# SYSCTRL_PADCONF_CORE register map
Vendor: Texas Instruments
Registers are 32-bit, access per field, reset 0x10F010F unless marked. A register's access mark holds for its fields unless they carry their own. Offsets are as the file gives them; [hi:lo] are bit positions; 'fields as' and 'values as' point back to an identical list.

## SYSCTRL_PADCONF_CORE (part 3 of 10)
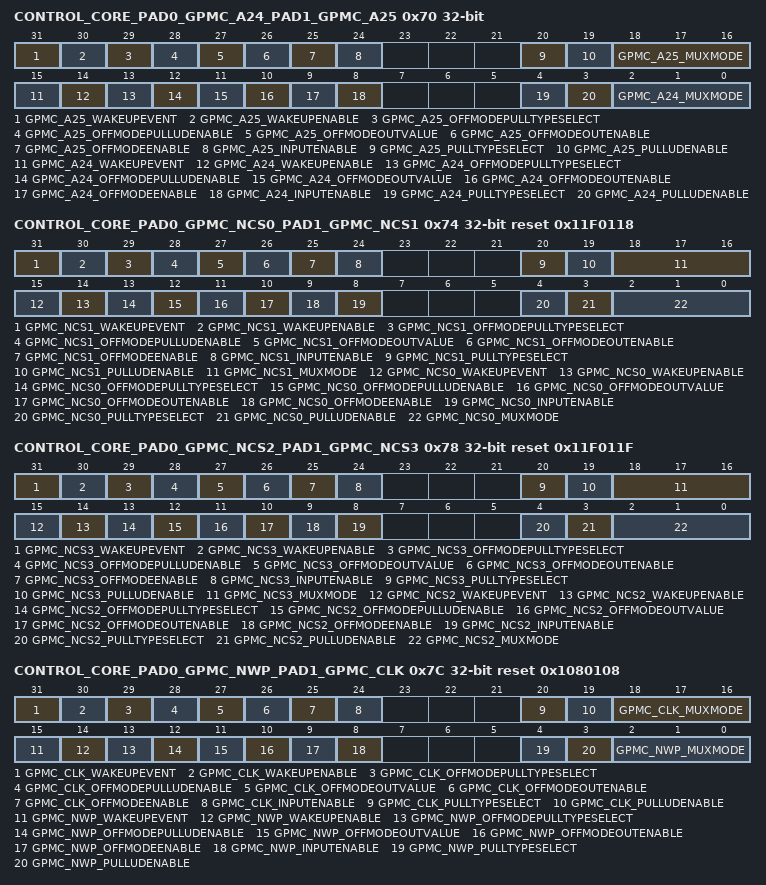
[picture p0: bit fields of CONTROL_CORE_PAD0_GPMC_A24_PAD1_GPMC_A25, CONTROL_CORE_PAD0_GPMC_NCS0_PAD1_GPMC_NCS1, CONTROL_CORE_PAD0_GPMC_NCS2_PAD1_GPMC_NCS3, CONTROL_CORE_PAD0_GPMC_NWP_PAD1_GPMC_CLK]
0x70 CONTROL_CORE_PAD0_GPMC_A24_PAD1_GPMC_A25 — Register control for Pads gpmc_a24 and gpmc_a25 Access conditions. Read: unrestricted, Write: unrestricted
  [31] GPMC_A25_WAKEUPEVENT ro — Pad_x wake-up event status latched in the IO
    0=GPMC_A25_WAKEUPEVENT_0_r (No wake-up event occurred); 1=GPMC_A25_WAKEUPEVENT_1_r (A wake-up event occurred)
  [30] GPMC_A25_WAKEUPENABLE rw — Input pad wake-up enable (and OFF mode input enable value)
    0=wake-up detection is disabled; 1=wake-up detection is enabled
  [29] GPMC_A25_OFFMODEPULLTYPESELECT rw — OffMode mode pullup/down selection for pad gpmc_a25
    0=Offmode pulldown selected; 1=Offmode pullup selected
  [28] GPMC_A25_OFFMODEPULLUDENABLE rw — OffMode mode pullup/down enable for pad gpmc_a25
    0=Offmode pullup/down disabled; 1=Offmode pullup/down enabled
  [27] GPMC_A25_OFFMODEOUTVALUE rw — OffMode mode output value for pad gpmc_a25
    0=Set value at 0; 1=Set value at 1
  [26] GPMC_A25_OFFMODEOUTENABLE rw — OffMode mode output enable value for pad gpmc_a25. This is an active low signal
    0=Output enable; 1=Output disable
  [25] GPMC_A25_OFFMODEENABLE rw — OffMode mode override control for pad gpmc_a25
    0=I/O state keeps its previous state when OFF mode is active; 1=I/O state is forced to OFF mode value when OFF mode is active
  [24] GPMC_A25_INPUTENABLE rw — Input enable value for pad gpmc_a25
    0=Input buffer of I/O cell is disabled; 1=Input buffer of I/O cell is enabled
  [20] GPMC_A25_PULLTYPESELECT rw — pullup/down selection for pad gpmc_a25
    0=pulldown selected; 1=pullup selected
  [19] GPMC_A25_PULLUDENABLE rw — pullup/down enable for pad gpmc_a25
    0=pullup/down disabled; 1=pullup/down enabled
  [18:16] GPMC_A25_MUXMODE rw — Functional multiplexing selection for pad gpmc_a25
    0=Select gpmc_a25; 2=Select c2c_clkout1; 3=Select gpio_49; 7=Select safe_mode
  [15] GPMC_A24_WAKEUPEVENT ro — Pad_x wake-up event status latched in the IO
    0=GPMC_A24_WAKEUPEVENT_0_r (No wake-up event occurred); 1=GPMC_A24_WAKEUPEVENT_1_r (A wake-up event occurred)
  [14] GPMC_A24_WAKEUPENABLE rw — Input pad wake-up enable (and OFF mode input enable value)
    values as GPMC_A25_WAKEUPENABLE
  [13] GPMC_A24_OFFMODEPULLTYPESELECT rw — OffMode mode pullup/down selection for pad gpmc_a24
    0=Offmode pulldown selected; 1=Offmode pullup selected
  [12] GPMC_A24_OFFMODEPULLUDENABLE rw — OffMode mode pullup/down enable for pad gpmc_a24
    values as GPMC_A25_OFFMODEPULLUDENABLE
  [11] GPMC_A24_OFFMODEOUTVALUE rw — OffMode mode output value for pad gpmc_a24
    0=Set value at 0; 1=Set value at 1
  [10] GPMC_A24_OFFMODEOUTENABLE rw — OffMode mode output enable value for pad gpmc_a24. This is an active low signal
    0=Output enable; 1=Output disable
  [9] GPMC_A24_OFFMODEENABLE rw — OffMode mode override control for pad gpmc_a24
    values as GPMC_A25_OFFMODEENABLE
  [8] GPMC_A24_INPUTENABLE rw — Input enable value for pad gpmc_a24
    values as GPMC_A25_INPUTENABLE
  [4] GPMC_A24_PULLTYPESELECT rw — pullup/down selection for pad gpmc_a24
    0=pulldown selected; 1=pullup selected
  [3] GPMC_A24_PULLUDENABLE rw — pullup/down enable for pad gpmc_a24
    0=pullup/down disabled; 1=pullup/down enabled
  [2:0] GPMC_A24_MUXMODE rw — Functional multiplexing selection for pad gpmc_a24
    0=Select gpmc_a24; 1=Select kpd_col8; 2=Select c2c_clkout0; 3=Select gpio_48; 7=Select safe_mode
0x74 CONTROL_CORE_PAD0_GPMC_NCS0_PAD1_GPMC_NCS1 reset 0x11F0118 — Register control for Pads gpmc_ncs0 and gpmc_ncs1 Access conditions. Read: unrestricted, Write: unrestricted
  [31] GPMC_NCS1_WAKEUPEVENT ro — Pad_x wake-up event status latched in the IO
    0=GPMC_NCS1_WAKEUPEVENT_0_r (No wake-up event occurred); 1=GPMC_NCS1_WAKEUPEVENT_1_r (A wake-up event occurred)
  [30] GPMC_NCS1_WAKEUPENABLE rw — Input pad wake-up enable (and OFF mode input enable value)
    values as CONTROL_CORE_PAD0_GPMC_A24_PAD1_GPMC_A25.GPMC_A25_WAKEUPENABLE
  [29] GPMC_NCS1_OFFMODEPULLTYPESELECT rw — OffMode mode pullup/down selection for pad gpmc_ncs1
    0=Offmode pulldown selected; 1=Offmode pullup selected
  [28] GPMC_NCS1_OFFMODEPULLUDENABLE rw — OffMode mode pullup/down enable for pad gpmc_ncs1
    values as CONTROL_CORE_PAD0_GPMC_A24_PAD1_GPMC_A25.GPMC_A25_OFFMODEPULLUDENABLE
  [27] GPMC_NCS1_OFFMODEOUTVALUE rw — OffMode mode output value for pad gpmc_ncs1
    0=Set value at 0; 1=Set value at 1
  [26] GPMC_NCS1_OFFMODEOUTENABLE rw — OffMode mode output enable value for pad gpmc_ncs1. This is an active low signal
    0=Output enable; 1=Output disable
  [25] GPMC_NCS1_OFFMODEENABLE rw — OffMode mode override control for pad gpmc_ncs1
    values as CONTROL_CORE_PAD0_GPMC_A24_PAD1_GPMC_A25.GPMC_A25_OFFMODEENABLE
  [24] GPMC_NCS1_INPUTENABLE rw — Input enable value for pad gpmc_ncs1
    values as CONTROL_CORE_PAD0_GPMC_A24_PAD1_GPMC_A25.GPMC_A25_INPUTENABLE
  [20] GPMC_NCS1_PULLTYPESELECT rw — pullup/down selection for pad gpmc_ncs1
    0=pulldown selected; 1=pullup selected
  [19] GPMC_NCS1_PULLUDENABLE rw — pullup/down enable for pad gpmc_ncs1
    0=pullup/down disabled; 1=pullup/down enabled
  [18:16] GPMC_NCS1_MUXMODE rw — Functional multiplexing selection for pad gpmc_ncs1
    0=Select gpmc_ncs1; 2=Select c2c_dataout6; 3=Select gpio_51; 7=Select safe_mode
  [15] GPMC_NCS0_WAKEUPEVENT ro — Pad_x wake-up event status latched in the IO
    0=GPMC_NCS0_WAKEUPEVENT_0_r (No wake-up event occurred); 1=GPMC_NCS0_WAKEUPEVENT_1_r (A wake-up event occurred)
  [14] GPMC_NCS0_WAKEUPENABLE rw — Input pad wake-up enable (and OFF mode input enable value)
    values as CONTROL_CORE_PAD0_GPMC_A24_PAD1_GPMC_A25.GPMC_A25_WAKEUPENABLE
  [13] GPMC_NCS0_OFFMODEPULLTYPESELECT rw — OffMode mode pullup/down selection for pad gpmc_ncs0
    0=Offmode pulldown selected; 1=Offmode pullup selected
  [12] GPMC_NCS0_OFFMODEPULLUDENABLE rw — OffMode mode pullup/down enable for pad gpmc_ncs0
    values as CONTROL_CORE_PAD0_GPMC_A24_PAD1_GPMC_A25.GPMC_A25_OFFMODEPULLUDENABLE
  [11] GPMC_NCS0_OFFMODEOUTVALUE rw — OffMode mode output value for pad gpmc_ncs0
    0=Set value at 0; 1=Set value at 1
  [10] GPMC_NCS0_OFFMODEOUTENABLE rw — OffMode mode output enable value for pad gpmc_ncs0. This is an active low signal
    0=Output enable; 1=Output disable
  [9] GPMC_NCS0_OFFMODEENABLE rw — OffMode mode override control for pad gpmc_ncs0
    values as CONTROL_CORE_PAD0_GPMC_A24_PAD1_GPMC_A25.GPMC_A25_OFFMODEENABLE
  [8] GPMC_NCS0_INPUTENABLE rw — Input enable value for pad gpmc_ncs0
    values as CONTROL_CORE_PAD0_GPMC_A24_PAD1_GPMC_A25.GPMC_A25_INPUTENABLE
  [4] GPMC_NCS0_PULLTYPESELECT rw — pullup/down selection for pad gpmc_ncs0
    0=pulldown selected; 1=pullup selected
  [3] GPMC_NCS0_PULLUDENABLE rw — pullup/down enable for pad gpmc_ncs0
    0=pullup/down disabled; 1=pullup/down enabled
  [2:0] GPMC_NCS0_MUXMODE rw — Functional multiplexing selection for pad gpmc_ncs0
    0=Select gpmc_ncs0; 3=Select gpio_50; 4=Select sys_ndmareq0
0x78 CONTROL_CORE_PAD0_GPMC_NCS2_PAD1_GPMC_NCS3 reset 0x11F011F — Register control for Pads gpmc_ncs2 and gpmc_ncs3 Access conditions. Read: unrestricted, Write: unrestricted
  [31] GPMC_NCS3_WAKEUPEVENT ro — Pad_x wake-up event status latched in the IO
    0=GPMC_NCS3_WAKEUPEVENT_0_r (No wake-up event occurred); 1=GPMC_NCS3_WAKEUPEVENT_1_r (A wake-up event occurred)
  [30] GPMC_NCS3_WAKEUPENABLE rw — Input pad wake-up enable (and OFF mode input enable value)
    values as CONTROL_CORE_PAD0_GPMC_A24_PAD1_GPMC_A25.GPMC_A25_WAKEUPENABLE
  [29] GPMC_NCS3_OFFMODEPULLTYPESELECT rw — OffMode mode pullup/down selection for pad gpmc_ncs3
    0=Offmode pulldown selected; 1=Offmode pullup selected
  [28] GPMC_NCS3_OFFMODEPULLUDENABLE rw — OffMode mode pullup/down enable for pad gpmc_ncs3
    values as CONTROL_CORE_PAD0_GPMC_A24_PAD1_GPMC_A25.GPMC_A25_OFFMODEPULLUDENABLE
  [27] GPMC_NCS3_OFFMODEOUTVALUE rw — OffMode mode output value for pad gpmc_ncs3
    0=Set value at 0; 1=Set value at 1
  [26] GPMC_NCS3_OFFMODEOUTENABLE rw — OffMode mode output enable value for pad gpmc_ncs3. This is an active low signal
    0=Output enable; 1=Output disable
  [25] GPMC_NCS3_OFFMODEENABLE rw — OffMode mode override control for pad gpmc_ncs3
    values as CONTROL_CORE_PAD0_GPMC_A24_PAD1_GPMC_A25.GPMC_A25_OFFMODEENABLE
  [24] GPMC_NCS3_INPUTENABLE rw — Input enable value for pad gpmc_ncs3
    values as CONTROL_CORE_PAD0_GPMC_A24_PAD1_GPMC_A25.GPMC_A25_INPUTENABLE
  [20] GPMC_NCS3_PULLTYPESELECT rw — pullup/down selection for pad gpmc_ncs3
    0=pulldown selected; 1=pullup selected
  [19] GPMC_NCS3_PULLUDENABLE rw — pullup/down enable for pad gpmc_ncs3
    0=pullup/down disabled; 1=pullup/down enabled
  [18:16] GPMC_NCS3_MUXMODE rw — Functional multiplexing selection for pad gpmc_ncs3
    0=Select gpmc_ncs3; 1=Select gpmc_dir; 2=Select c2c_dataout4; 3=Select gpio_53; 7=Select safe_mode
  [15] GPMC_NCS2_WAKEUPEVENT ro — Pad_x wake-up event status latched in the IO
    0=GPMC_NCS2_WAKEUPEVENT_0_r (No wake-up event occurred); 1=GPMC_NCS2_WAKEUPEVENT_1_r (A wake-up event occurred)
  [14] GPMC_NCS2_WAKEUPENABLE rw — Input pad wake-up enable (and OFF mode input enable value)
    values as CONTROL_CORE_PAD0_GPMC_A24_PAD1_GPMC_A25.GPMC_A25_WAKEUPENABLE
  [13] GPMC_NCS2_OFFMODEPULLTYPESELECT rw — OffMode mode pullup/down selection for pad gpmc_ncs2
    0=Offmode pulldown selected; 1=Offmode pullup selected
  [12] GPMC_NCS2_OFFMODEPULLUDENABLE rw — OffMode mode pullup/down enable for pad gpmc_ncs2
    values as CONTROL_CORE_PAD0_GPMC_A24_PAD1_GPMC_A25.GPMC_A25_OFFMODEPULLUDENABLE
  [11] GPMC_NCS2_OFFMODEOUTVALUE rw — OffMode mode output value for pad gpmc_ncs2
    0=Set value at 0; 1=Set value at 1
  [10] GPMC_NCS2_OFFMODEOUTENABLE rw — OffMode mode output enable value for pad gpmc_ncs2. This is an active low signal
    0=Output enable; 1=Output disable
  [9] GPMC_NCS2_OFFMODEENABLE rw — OffMode mode override control for pad gpmc_ncs2
    values as CONTROL_CORE_PAD0_GPMC_A24_PAD1_GPMC_A25.GPMC_A25_OFFMODEENABLE
  [8] GPMC_NCS2_INPUTENABLE rw — Input enable value for pad gpmc_ncs2
    values as CONTROL_CORE_PAD0_GPMC_A24_PAD1_GPMC_A25.GPMC_A25_INPUTENABLE
  [4] GPMC_NCS2_PULLTYPESELECT rw — pullup/down selection for pad gpmc_ncs2
    0=pulldown selected; 1=pullup selected
  [3] GPMC_NCS2_PULLUDENABLE rw — pullup/down enable for pad gpmc_ncs2
    0=pullup/down disabled; 1=pullup/down enabled
  [2:0] GPMC_NCS2_MUXMODE rw — Functional multiplexing selection for pad gpmc_ncs2
    0=Select gpmc_ncs2; 1=Select kpd_row8; 2=Select c2c_dataout7; 3=Select gpio_52; 7=Select safe_mode
0x7C CONTROL_CORE_PAD0_GPMC_NWP_PAD1_GPMC_CLK reset 0x1080108 — Register control for Pads gpmc_nwp and gpmc_clk Access conditions. Read: unrestricted, Write: unrestricted
  [31] GPMC_CLK_WAKEUPEVENT ro — Pad_x wake-up event status latched in the IO
    0=GPMC_CLK_WAKEUPEVENT_0_r (No wake-up event occurred); 1=GPMC_CLK_WAKEUPEVENT_1_r (A wake-up event occurred)
  [30] GPMC_CLK_WAKEUPENABLE rw — Input pad wake-up enable (and OFF mode input enable value)
    values as CONTROL_CORE_PAD0_GPMC_A24_PAD1_GPMC_A25.GPMC_A25_WAKEUPENABLE
  [29] GPMC_CLK_OFFMODEPULLTYPESELECT rw — OffMode mode pullup/down selection for pad gpmc_clk
    0=Offmode pulldown selected; 1=Offmode pullup selected
  [28] GPMC_CLK_OFFMODEPULLUDENABLE rw — OffMode mode pullup/down enable for pad gpmc_clk
    values as CONTROL_CORE_PAD0_GPMC_A24_PAD1_GPMC_A25.GPMC_A25_OFFMODEPULLUDENABLE
  [27] GPMC_CLK_OFFMODEOUTVALUE rw — OffMode mode output value for pad gpmc_clk
    0=Set value at 0; 1=Set value at 1
  [26] GPMC_CLK_OFFMODEOUTENABLE rw — OffMode mode output enable value for pad gpmc_clk. This is an active low signal
    0=Output enable; 1=Output disable
  [25] GPMC_CLK_OFFMODEENABLE rw — OffMode mode override control for pad gpmc_clk
    values as CONTROL_CORE_PAD0_GPMC_A24_PAD1_GPMC_A25.GPMC_A25_OFFMODEENABLE
  [24] GPMC_CLK_INPUTENABLE rw — Input enable value for pad gpmc_clk
    values as CONTROL_CORE_PAD0_GPMC_A24_PAD1_GPMC_A25.GPMC_A25_INPUTENABLE
  [20] GPMC_CLK_PULLTYPESELECT rw — pullup/down selection for pad gpmc_clk
    0=pulldown selected; 1=pullup selected
  [19] GPMC_CLK_PULLUDENABLE rw — pullup/down enable for pad gpmc_clk
    0=pullup/down disabled; 1=pullup/down enabled
  [18:16] GPMC_CLK_MUXMODE rw — Functional multiplexing selection for pad gpmc_clk
    0=Select gpmc_clk; 3=Select gpio_55; 4=Select sys_ndmareq2; 5=Select sdmmc1_cmd
  [15] GPMC_NWP_WAKEUPEVENT ro — Pad_x wake-up event status latched in the IO
    0=GPMC_NWP_WAKEUPEVENT_0_r (No wake-up event occurred); 1=GPMC_NWP_WAKEUPEVENT_1_r (A wake-up event occurred)
  [14] GPMC_NWP_WAKEUPENABLE rw — Input pad wake-up enable (and OFF mode input enable value)
    values as CONTROL_CORE_PAD0_GPMC_A24_PAD1_GPMC_A25.GPMC_A25_WAKEUPENABLE
  [13] GPMC_NWP_OFFMODEPULLTYPESELECT rw — OffMode mode pullup/down selection for pad gpmc_nwp
    0=Offmode pulldown selected; 1=Offmode pullup selected
  [12] GPMC_NWP_OFFMODEPULLUDENABLE rw — OffMode mode pullup/down enable for pad gpmc_nwp
    values as CONTROL_CORE_PAD0_GPMC_A24_PAD1_GPMC_A25.GPMC_A25_OFFMODEPULLUDENABLE
  [11] GPMC_NWP_OFFMODEOUTVALUE rw — OffMode mode output value for pad gpmc_nwp
    0=Set value at 0; 1=Set value at 1
  [10] GPMC_NWP_OFFMODEOUTENABLE rw — OffMode mode output enable value for pad gpmc_nwp. This is an active low signal
    0=Output enable; 1=Output disable
  [9] GPMC_NWP_OFFMODEENABLE rw — OffMode mode override control for pad gpmc_nwp
    values as CONTROL_CORE_PAD0_GPMC_A24_PAD1_GPMC_A25.GPMC_A25_OFFMODEENABLE
  [8] GPMC_NWP_INPUTENABLE rw — Input enable value for pad gpmc_nwp
    values as CONTROL_CORE_PAD0_GPMC_A24_PAD1_GPMC_A25.GPMC_A25_INPUTENABLE
  [4] GPMC_NWP_PULLTYPESELECT rw — pullup/down selection for pad gpmc_nwp
    0=pulldown selected; 1=pullup selected
  [3] GPMC_NWP_PULLUDENABLE rw — pullup/down enable for pad gpmc_nwp
    0=pullup/down disabled; 1=pullup/down enabled
  [2:0] GPMC_NWP_MUXMODE rw — Functional multiplexing selection for pad gpmc_nwp
    0=Select gpmc_nwp; 1=Select dsi1_te0; 3=Select gpio_54; 4=Select sys_ndmareq1
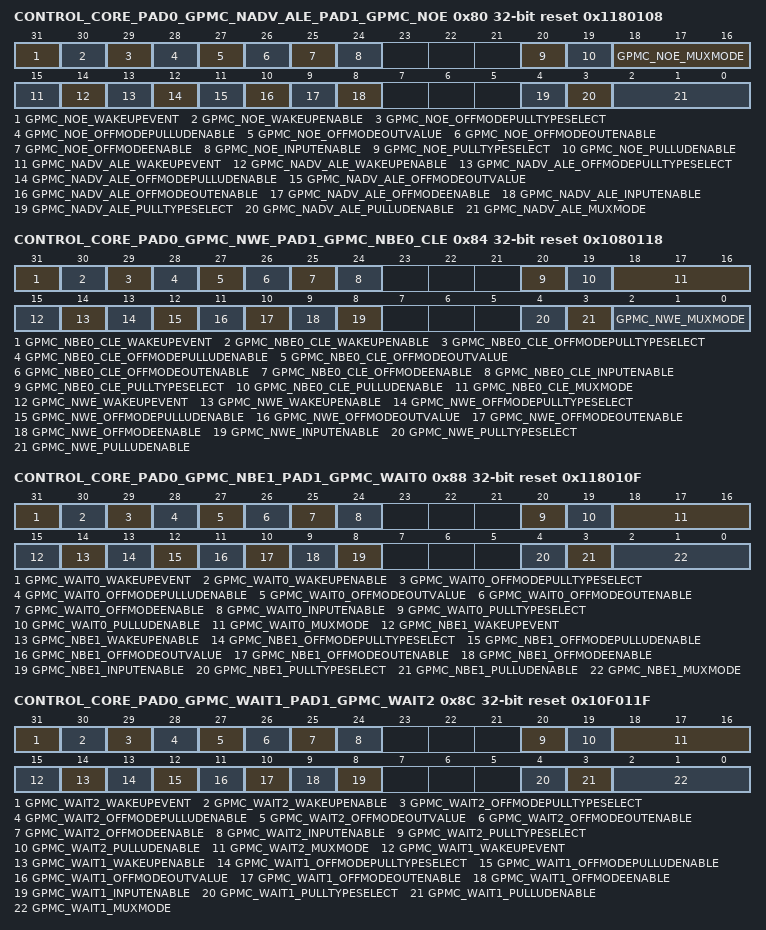
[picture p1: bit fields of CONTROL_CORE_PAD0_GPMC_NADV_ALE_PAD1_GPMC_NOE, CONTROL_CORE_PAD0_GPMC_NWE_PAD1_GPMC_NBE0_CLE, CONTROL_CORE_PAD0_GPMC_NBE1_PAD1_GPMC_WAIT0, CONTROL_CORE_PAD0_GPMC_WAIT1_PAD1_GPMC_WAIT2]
0x80 CONTROL_CORE_PAD0_GPMC_NADV_ALE_PAD1_GPMC_NOE reset 0x1180108 — Register control for Pads gpmc_nadv_ale and gpmc_noe Access conditions. Read: unrestricted, Write: unrestricted
  [31] GPMC_NOE_WAKEUPEVENT ro — Pad_x wake-up event status latched in the IO
    0=GPMC_NOE_WAKEUPEVENT_0_r (No wake-up event occurred); 1=GPMC_NOE_WAKEUPEVENT_1_r (A wake-up event occurred)
  [30] GPMC_NOE_WAKEUPENABLE rw — Input pad wake-up enable (and OFF mode input enable value)
    values as CONTROL_CORE_PAD0_GPMC_A24_PAD1_GPMC_A25.GPMC_A25_WAKEUPENABLE
  [29] GPMC_NOE_OFFMODEPULLTYPESELECT rw — OffMode mode pullup/down selection for pad gpmc_noe
    0=Offmode pulldown selected; 1=Offmode pullup selected
  [28] GPMC_NOE_OFFMODEPULLUDENABLE rw — OffMode mode pullup/down enable for pad gpmc_noe
    values as CONTROL_CORE_PAD0_GPMC_A24_PAD1_GPMC_A25.GPMC_A25_OFFMODEPULLUDENABLE
  [27] GPMC_NOE_OFFMODEOUTVALUE rw — OffMode mode output value for pad gpmc_noe
    0=Set value at 0; 1=Set value at 1
  [26] GPMC_NOE_OFFMODEOUTENABLE rw — OffMode mode output enable value for pad gpmc_noe. This is an active low signal
    0=Output enable; 1=Output disable
  [25] GPMC_NOE_OFFMODEENABLE rw — OffMode mode override control for pad gpmc_noe
    values as CONTROL_CORE_PAD0_GPMC_A24_PAD1_GPMC_A25.GPMC_A25_OFFMODEENABLE
  [24] GPMC_NOE_INPUTENABLE rw — Input enable value for pad gpmc_noe
    values as CONTROL_CORE_PAD0_GPMC_A24_PAD1_GPMC_A25.GPMC_A25_INPUTENABLE
  [20] GPMC_NOE_PULLTYPESELECT rw — pullup/down selection for pad gpmc_noe
    0=pulldown selected; 1=pullup selected
  [19] GPMC_NOE_PULLUDENABLE rw — pullup/down enable for pad gpmc_noe
    0=pullup/down disabled; 1=pullup/down enabled
  [18:16] GPMC_NOE_MUXMODE rw — Functional multiplexing selection for pad gpmc_noe
    0=Select gpmc_noe; 1=Select sdmmc2_clk
  [15] GPMC_NADV_ALE_WAKEUPEVENT ro — Pad_x wake-up event status latched in the IO
    0=GPMC_NADV_ALE_WAKEUPEVENT_0_r (No wake-up event occurred); 1=GPMC_NADV_ALE_WAKEUPEVENT_1_r (A wake-up event occurred)
  [14] GPMC_NADV_ALE_WAKEUPENABLE rw — Input pad wake-up enable (and OFF mode input enable value)
    values as CONTROL_CORE_PAD0_GPMC_A24_PAD1_GPMC_A25.GPMC_A25_WAKEUPENABLE
  [13] GPMC_NADV_ALE_OFFMODEPULLTYPESELECT rw — OffMode mode pullup/down selection for pad gpmc_nadv_ale
    0=Offmode pulldown selected; 1=Offmode pullup selected
  [12] GPMC_NADV_ALE_OFFMODEPULLUDENABLE rw — OffMode mode pullup/down enable for pad gpmc_nadv_ale
    values as CONTROL_CORE_PAD0_GPMC_A24_PAD1_GPMC_A25.GPMC_A25_OFFMODEPULLUDENABLE
  [11] GPMC_NADV_ALE_OFFMODEOUTVALUE rw — OffMode mode output value for pad gpmc_nadv_ale
    0=Set value at 0; 1=Set value at 1
  [10] GPMC_NADV_ALE_OFFMODEOUTENABLE rw — OffMode mode output enable value for pad gpmc_nadv_ale. This is an active low signal
    0=Output enable; 1=Output disable
  [9] GPMC_NADV_ALE_OFFMODEENABLE rw — OffMode mode override control for pad gpmc_nadv_ale
    values as CONTROL_CORE_PAD0_GPMC_A24_PAD1_GPMC_A25.GPMC_A25_OFFMODEENABLE
  [8] GPMC_NADV_ALE_INPUTENABLE rw — Input enable value for pad gpmc_nadv_ale
    values as CONTROL_CORE_PAD0_GPMC_A24_PAD1_GPMC_A25.GPMC_A25_INPUTENABLE
  [4] GPMC_NADV_ALE_PULLTYPESELECT rw — pullup/down selection for pad gpmc_nadv_ale
    0=pulldown selected; 1=pullup selected
  [3] GPMC_NADV_ALE_PULLUDENABLE rw — pullup/down enable for pad gpmc_nadv_ale
    0=pullup/down disabled; 1=pullup/down enabled
  [2:0] GPMC_NADV_ALE_MUXMODE rw — Functional multiplexing selection for pad gpmc_nadv_ale
    0=Select gpmc_nadv_ale; 1=Select dsi1_te1; 3=Select gpio_56; 4=Select sys_ndmareq3; 5=Select sdmmc1_clk
0x84 CONTROL_CORE_PAD0_GPMC_NWE_PAD1_GPMC_NBE0_CLE reset 0x1080118 — Register control for Pads gpmc_nwe and gpmc_nbe0_cle Access conditions. Read: unrestricted, Write: unrestricted
  [31] GPMC_NBE0_CLE_WAKEUPEVENT ro — Pad_x wake-up event status latched in the IO
    0=GPMC_NBE0_CLE_WAKEUPEVENT_0_r (No wake-up event occurred); 1=GPMC_NBE0_CLE_WAKEUPEVENT_1_r (A wake-up event occurred)
  [30] GPMC_NBE0_CLE_WAKEUPENABLE rw — Input pad wake-up enable (and OFF mode input enable value)
    values as CONTROL_CORE_PAD0_GPMC_A24_PAD1_GPMC_A25.GPMC_A25_WAKEUPENABLE
  [29] GPMC_NBE0_CLE_OFFMODEPULLTYPESELECT rw — OffMode mode pullup/down selection for pad gpmc_nbe0_cle
    0=Offmode pulldown selected; 1=Offmode pullup selected
  [28] GPMC_NBE0_CLE_OFFMODEPULLUDENABLE rw — OffMode mode pullup/down enable for pad gpmc_nbe0_cle
    values as CONTROL_CORE_PAD0_GPMC_A24_PAD1_GPMC_A25.GPMC_A25_OFFMODEPULLUDENABLE
  [27] GPMC_NBE0_CLE_OFFMODEOUTVALUE rw — OffMode mode output value for pad gpmc_nbe0_cle
    0=Set value at 0; 1=Set value at 1
  [26] GPMC_NBE0_CLE_OFFMODEOUTENABLE rw — OffMode mode output enable value for pad gpmc_nbe0_cle. This is an active low signal
    0=Output enable; 1=Output disable
  [25] GPMC_NBE0_CLE_OFFMODEENABLE rw — OffMode mode override control for pad gpmc_nbe0_cle
    values as CONTROL_CORE_PAD0_GPMC_A24_PAD1_GPMC_A25.GPMC_A25_OFFMODEENABLE
  [24] GPMC_NBE0_CLE_INPUTENABLE rw — Input enable value for pad gpmc_nbe0_cle
    values as CONTROL_CORE_PAD0_GPMC_A24_PAD1_GPMC_A25.GPMC_A25_INPUTENABLE
  [20] GPMC_NBE0_CLE_PULLTYPESELECT rw — pullup/down selection for pad gpmc_nbe0_cle
    0=pulldown selected; 1=pullup selected
  [19] GPMC_NBE0_CLE_PULLUDENABLE rw — pullup/down enable for pad gpmc_nbe0_cle
    0=pullup/down disabled; 1=pullup/down enabled
  [18:16] GPMC_NBE0_CLE_MUXMODE rw — Functional multiplexing selection for pad gpmc_nbe0_cle
    0=Select gpmc_nbe0_cle; 1=Select dsi2_te0; 3=Select gpio_59
  [15] GPMC_NWE_WAKEUPEVENT ro — Pad_x wake-up event status latched in the IO
    0=GPMC_NWE_WAKEUPEVENT_0_r (No wake-up event occurred); 1=GPMC_NWE_WAKEUPEVENT_1_r (A wake-up event occurred)
  [14] GPMC_NWE_WAKEUPENABLE rw — Input pad wake-up enable (and OFF mode input enable value)
    values as CONTROL_CORE_PAD0_GPMC_A24_PAD1_GPMC_A25.GPMC_A25_WAKEUPENABLE
  [13] GPMC_NWE_OFFMODEPULLTYPESELECT rw — OffMode mode pullup/down selection for pad gpmc_nwe
    0=Offmode pulldown selected; 1=Offmode pullup selected
  [12] GPMC_NWE_OFFMODEPULLUDENABLE rw — OffMode mode pullup/down enable for pad gpmc_nwe
    values as CONTROL_CORE_PAD0_GPMC_A24_PAD1_GPMC_A25.GPMC_A25_OFFMODEPULLUDENABLE
  [11] GPMC_NWE_OFFMODEOUTVALUE rw — OffMode mode output value for pad gpmc_nwe
    0=Set value at 0; 1=Set value at 1
  [10] GPMC_NWE_OFFMODEOUTENABLE rw — OffMode mode output enable value for pad gpmc_nwe. This is an active low signal
    0=Output enable; 1=Output disable
  [9] GPMC_NWE_OFFMODEENABLE rw — OffMode mode override control for pad gpmc_nwe
    values as CONTROL_CORE_PAD0_GPMC_A24_PAD1_GPMC_A25.GPMC_A25_OFFMODEENABLE
  [8] GPMC_NWE_INPUTENABLE rw — Input enable value for pad gpmc_nwe
    values as CONTROL_CORE_PAD0_GPMC_A24_PAD1_GPMC_A25.GPMC_A25_INPUTENABLE
  [4] GPMC_NWE_PULLTYPESELECT rw — pullup/down selection for pad gpmc_nwe
    0=pulldown selected; 1=pullup selected
  [3] GPMC_NWE_PULLUDENABLE rw — pullup/down enable for pad gpmc_nwe
    0=pullup/down disabled; 1=pullup/down enabled
  [2:0] GPMC_NWE_MUXMODE rw — Functional multiplexing selection for pad gpmc_nwe
    0=Select gpmc_nwe; 1=Select sdmmc2_cmd
0x88 CONTROL_CORE_PAD0_GPMC_NBE1_PAD1_GPMC_WAIT0 reset 0x118010F — Register control for Pads gpmc_nbe1 and gpmc_wait0 Access conditions. Read: unrestricted, Write: unrestricted
  [31] GPMC_WAIT0_WAKEUPEVENT ro — Pad_x wake-up event status latched in the IO
    0=GPMC_WAIT0_WAKEUPEVENT_0_r (No wake-up event occurred); 1=GPMC_WAIT0_WAKEUPEVENT_1_r (A wake-up event occurred)
  [30] GPMC_WAIT0_WAKEUPENABLE rw — Input pad wake-up enable (and OFF mode input enable value)
    values as CONTROL_CORE_PAD0_GPMC_A24_PAD1_GPMC_A25.GPMC_A25_WAKEUPENABLE
  [29] GPMC_WAIT0_OFFMODEPULLTYPESELECT rw — OffMode mode pullup/down selection for pad gpmc_wait0
    0=Offmode pulldown selected; 1=Offmode pullup selected
  [28] GPMC_WAIT0_OFFMODEPULLUDENABLE rw — OffMode mode pullup/down enable for pad gpmc_wait0
    values as CONTROL_CORE_PAD0_GPMC_A24_PAD1_GPMC_A25.GPMC_A25_OFFMODEPULLUDENABLE
  [27] GPMC_WAIT0_OFFMODEOUTVALUE rw — OffMode mode output value for pad gpmc_wait0
    0=Set value at 0; 1=Set value at 1
  [26] GPMC_WAIT0_OFFMODEOUTENABLE rw — OffMode mode output enable value for pad gpmc_wait0. This is an active low signal
    0=Output enable; 1=Output disable
  [25] GPMC_WAIT0_OFFMODEENABLE rw — OffMode mode override control for pad gpmc_wait0
    values as CONTROL_CORE_PAD0_GPMC_A24_PAD1_GPMC_A25.GPMC_A25_OFFMODEENABLE
  [24] GPMC_WAIT0_INPUTENABLE rw — Input enable value for pad gpmc_wait0
    values as CONTROL_CORE_PAD0_GPMC_A24_PAD1_GPMC_A25.GPMC_A25_INPUTENABLE
  [20] GPMC_WAIT0_PULLTYPESELECT rw — pullup/down selection for pad gpmc_wait0
    0=pulldown selected; 1=pullup selected
  [19] GPMC_WAIT0_PULLUDENABLE rw — pullup/down enable for pad gpmc_wait0
    0=pullup/down disabled; 1=pullup/down enabled
  [18:16] GPMC_WAIT0_MUXMODE rw — Functional multiplexing selection for pad gpmc_wait0
    0=Select gpmc_wait0; 1=Select dsi2_te1; 3=Select gpio_61
  [15] GPMC_NBE1_WAKEUPEVENT ro — Pad_x wake-up event status latched in the IO
    0=GPMC_NBE1_WAKEUPEVENT_0_r (No wake-up event occurred); 1=GPMC_NBE1_WAKEUPEVENT_1_r (A wake-up event occurred)
  [14] GPMC_NBE1_WAKEUPENABLE rw — Input pad wake-up enable (and OFF mode input enable value)
    values as CONTROL_CORE_PAD0_GPMC_A24_PAD1_GPMC_A25.GPMC_A25_WAKEUPENABLE
  [13] GPMC_NBE1_OFFMODEPULLTYPESELECT rw — OffMode mode pullup/down selection for pad gpmc_nbe1
    0=Offmode pulldown selected; 1=Offmode pullup selected
  [12] GPMC_NBE1_OFFMODEPULLUDENABLE rw — OffMode mode pullup/down enable for pad gpmc_nbe1
    values as CONTROL_CORE_PAD0_GPMC_A24_PAD1_GPMC_A25.GPMC_A25_OFFMODEPULLUDENABLE
  [11] GPMC_NBE1_OFFMODEOUTVALUE rw — OffMode mode output value for pad gpmc_nbe1
    0=Set value at 0; 1=Set value at 1
  [10] GPMC_NBE1_OFFMODEOUTENABLE rw — OffMode mode output enable value for pad gpmc_nbe1. This is an active low signal
    0=Output enable; 1=Output disable
  [9] GPMC_NBE1_OFFMODEENABLE rw — OffMode mode override control for pad gpmc_nbe1
    values as CONTROL_CORE_PAD0_GPMC_A24_PAD1_GPMC_A25.GPMC_A25_OFFMODEENABLE
  [8] GPMC_NBE1_INPUTENABLE rw — Input enable value for pad gpmc_nbe1
    values as CONTROL_CORE_PAD0_GPMC_A24_PAD1_GPMC_A25.GPMC_A25_INPUTENABLE
  [4] GPMC_NBE1_PULLTYPESELECT rw — pullup/down selection for pad gpmc_nbe1
    0=pulldown selected; 1=pullup selected
  [3] GPMC_NBE1_PULLUDENABLE rw — pullup/down enable for pad gpmc_nbe1
    0=pullup/down disabled; 1=pullup/down enabled
  [2:0] GPMC_NBE1_MUXMODE rw — Functional multiplexing selection for pad gpmc_nbe1
    0=Select gpmc_nbe1; 2=Select c2c_dataout5; 3=Select gpio_60; 7=Select safe_mode
0x8C CONTROL_CORE_PAD0_GPMC_WAIT1_PAD1_GPMC_WAIT2 reset 0x10F011F — Register control for Pads gpmc_wait1 and gpmc_wait2 Access conditions. Read: unrestricted, Write: unrestricted
  [31] GPMC_WAIT2_WAKEUPEVENT ro — Pad_x wake-up event status latched in the IO
    0=GPMC_WAIT2_WAKEUPEVENT_0_r (No wake-up event occurred); 1=GPMC_WAIT2_WAKEUPEVENT_1_r (A wake-up event occurred)
  [30] GPMC_WAIT2_WAKEUPENABLE rw — Input pad wake-up enable (and OFF mode input enable value)
    values as CONTROL_CORE_PAD0_GPMC_A24_PAD1_GPMC_A25.GPMC_A25_WAKEUPENABLE
  [29] GPMC_WAIT2_OFFMODEPULLTYPESELECT rw — OffMode mode pullup/down selection for pad gpmc_wait2
    0=Offmode pulldown selected; 1=Offmode pullup selected
  [28] GPMC_WAIT2_OFFMODEPULLUDENABLE rw — OffMode mode pullup/down enable for pad gpmc_wait2
    values as CONTROL_CORE_PAD0_GPMC_A24_PAD1_GPMC_A25.GPMC_A25_OFFMODEPULLUDENABLE
  [27] GPMC_WAIT2_OFFMODEOUTVALUE rw — OffMode mode output value for pad gpmc_wait2
    0=Set value at 0; 1=Set value at 1
  [26] GPMC_WAIT2_OFFMODEOUTENABLE rw — OffMode mode output enable value for pad gpmc_wait2. This is an active low signal
    0=Output enable; 1=Output disable
  [25] GPMC_WAIT2_OFFMODEENABLE rw — OffMode mode override control for pad gpmc_wait2
    values as CONTROL_CORE_PAD0_GPMC_A24_PAD1_GPMC_A25.GPMC_A25_OFFMODEENABLE
  [24] GPMC_WAIT2_INPUTENABLE rw — Input enable value for pad gpmc_wait2
    values as CONTROL_CORE_PAD0_GPMC_A24_PAD1_GPMC_A25.GPMC_A25_INPUTENABLE
  [20] GPMC_WAIT2_PULLTYPESELECT rw — pullup/down selection for pad gpmc_wait2
    0=pulldown selected; 1=pullup selected
  [19] GPMC_WAIT2_PULLUDENABLE rw — pullup/down enable for pad gpmc_wait2
    0=pullup/down disabled; 1=pullup/down enabled
  [18:16] GPMC_WAIT2_MUXMODE rw — Functional multiplexing selection for pad gpmc_wait2
    0=Select gpmc_wait2; 1=Select usbc1_icusb_txen; 2=Select c2c_dataout3; 3=Select gpio_100; 4=Select sys_ndmareq0; 7=Select safe_mode
  [15] GPMC_WAIT1_WAKEUPEVENT ro — Pad_x wake-up event status latched in the IO
    0=GPMC_WAIT1_WAKEUPEVENT_0_r (No wake-up event occurred); 1=GPMC_WAIT1_WAKEUPEVENT_1_r (A wake-up event occurred)
  [14] GPMC_WAIT1_WAKEUPENABLE rw — Input pad wake-up enable (and OFF mode input enable value)
    values as CONTROL_CORE_PAD0_GPMC_A24_PAD1_GPMC_A25.GPMC_A25_WAKEUPENABLE
  [13] GPMC_WAIT1_OFFMODEPULLTYPESELECT rw — OffMode mode pullup/down selection for pad gpmc_wait1
    0=Offmode pulldown selected; 1=Offmode pullup selected
  [12] GPMC_WAIT1_OFFMODEPULLUDENABLE rw — OffMode mode pullup/down enable for pad gpmc_wait1
    values as CONTROL_CORE_PAD0_GPMC_A24_PAD1_GPMC_A25.GPMC_A25_OFFMODEPULLUDENABLE
  [11] GPMC_WAIT1_OFFMODEOUTVALUE rw — OffMode mode output value for pad gpmc_wait1
    0=Set value at 0; 1=Set value at 1
  [10] GPMC_WAIT1_OFFMODEOUTENABLE rw — OffMode mode output enable value for pad gpmc_wait1. This is an active low signal
    0=Output enable; 1=Output disable
  [9] GPMC_WAIT1_OFFMODEENABLE rw — OffMode mode override control for pad gpmc_wait1
    values as CONTROL_CORE_PAD0_GPMC_A24_PAD1_GPMC_A25.GPMC_A25_OFFMODEENABLE
  [8] GPMC_WAIT1_INPUTENABLE rw — Input enable value for pad gpmc_wait1
    values as CONTROL_CORE_PAD0_GPMC_A24_PAD1_GPMC_A25.GPMC_A25_INPUTENABLE
  [4] GPMC_WAIT1_PULLTYPESELECT rw — pullup/down selection for pad gpmc_wait1
    0=pulldown selected; 1=pullup selected
  [3] GPMC_WAIT1_PULLUDENABLE rw — pullup/down enable for pad gpmc_wait1
    0=pullup/down disabled; 1=pullup/down enabled
  [2:0] GPMC_WAIT1_MUXMODE rw — Functional multiplexing selection for pad gpmc_wait1
    0=Select gpmc_wait1; 2=Select c2c_dataout2; 3=Select gpio_62; 7=Select safe_mode
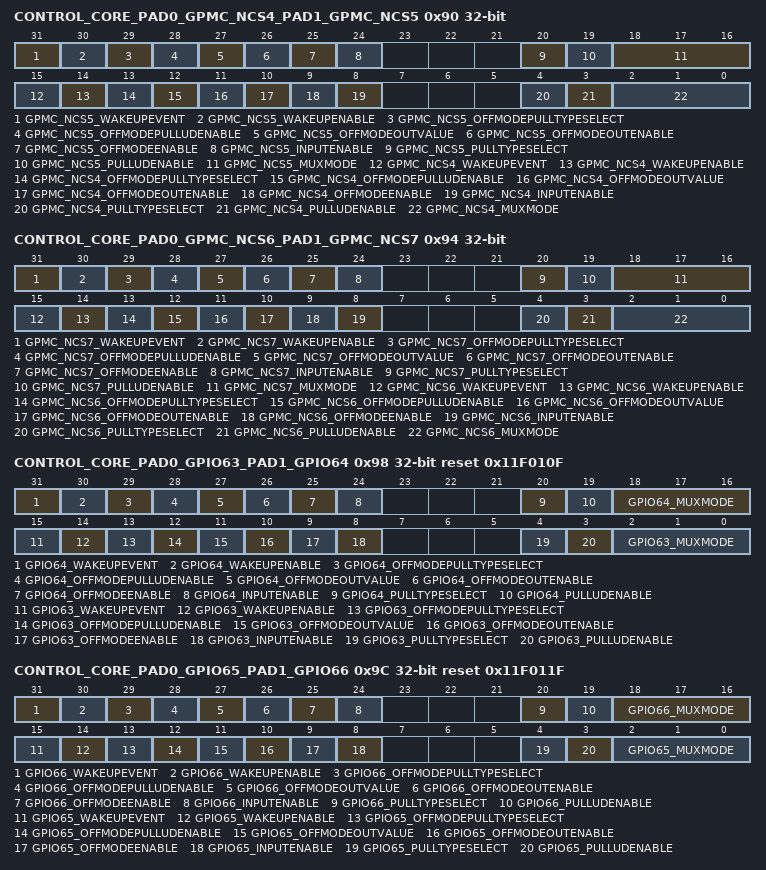
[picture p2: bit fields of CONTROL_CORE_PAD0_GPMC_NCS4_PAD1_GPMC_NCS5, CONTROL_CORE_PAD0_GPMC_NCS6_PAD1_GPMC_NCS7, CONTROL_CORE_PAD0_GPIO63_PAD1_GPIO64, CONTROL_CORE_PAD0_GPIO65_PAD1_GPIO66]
0x90 CONTROL_CORE_PAD0_GPMC_NCS4_PAD1_GPMC_NCS5 — Register control for Pads gpmc_ncs4 and gpmc_ncs5 Access conditions. Read: unrestricted, Write: unrestricted
  [31] GPMC_NCS5_WAKEUPEVENT ro — Pad_x wake-up event status latched in the IO
    0=GPMC_NCS5_WAKEUPEVENT_0_r (No wake-up event occurred); 1=GPMC_NCS5_WAKEUPEVENT_1_r (A wake-up event occurred)
  [30] GPMC_NCS5_WAKEUPENABLE rw — Input pad wake-up enable (and OFF mode input enable value)
    values as CONTROL_CORE_PAD0_GPMC_A24_PAD1_GPMC_A25.GPMC_A25_WAKEUPENABLE
  [29] GPMC_NCS5_OFFMODEPULLTYPESELECT rw — OffMode mode pullup/down selection for pad gpmc_ncs5
    0=Offmode pulldown selected; 1=Offmode pullup selected
  [28] GPMC_NCS5_OFFMODEPULLUDENABLE rw — OffMode mode pullup/down enable for pad gpmc_ncs5
    values as CONTROL_CORE_PAD0_GPMC_A24_PAD1_GPMC_A25.GPMC_A25_OFFMODEPULLUDENABLE
  [27] GPMC_NCS5_OFFMODEOUTVALUE rw — OffMode mode output value for pad gpmc_ncs5
    0=Set value at 0; 1=Set value at 1
  [26] GPMC_NCS5_OFFMODEOUTENABLE rw — OffMode mode output enable value for pad gpmc_ncs5 . This is an active low signal
    0=Output enable; 1=Output disable
  [25] GPMC_NCS5_OFFMODEENABLE rw — OffMode mode override control for pad gpmc_ncs5
    values as CONTROL_CORE_PAD0_GPMC_A24_PAD1_GPMC_A25.GPMC_A25_OFFMODEENABLE
  [24] GPMC_NCS5_INPUTENABLE rw — Input enable value for pad gpmc_ncs5
    values as CONTROL_CORE_PAD0_GPMC_A24_PAD1_GPMC_A25.GPMC_A25_INPUTENABLE
  [20] GPMC_NCS5_PULLTYPESELECT rw — pullup/down selection for pad gpmc_ncs5
    0=pulldown selected; 1=pullup selected
  [19] GPMC_NCS5_PULLUDENABLE rw — pullup/down enable for pad gpmc_ncs5
    0=pullup/down disabled; 1=pullup/down enabled
  [18:16] GPMC_NCS5_MUXMODE rw — Functional multiplexing selection for pad gpmc_ncs5
    0=Select gpmc_ncs5; 1=Select dsi1_te1; 2=Select c2c_clkin1; 3=Select gpio_102; 4=Select sys_ndmareq2; 7=Select safe_mode
  [15] GPMC_NCS4_WAKEUPEVENT ro — Pad_x wake-up event status latched in the IO
    0=GPMC_NCS4_WAKEUPEVENT_0_r (No wake-up event occurred); 1=GPMC_NCS4_WAKEUPEVENT_1_r (A wake-up event occurred)
  [14] GPMC_NCS4_WAKEUPENABLE rw — Input pad wake-up enable (and OFF mode input enable value)
    values as CONTROL_CORE_PAD0_GPMC_A24_PAD1_GPMC_A25.GPMC_A25_WAKEUPENABLE
  [13] GPMC_NCS4_OFFMODEPULLTYPESELECT rw — OffMode mode pullup/down selection for pad gpmc_ncs4
    0=Offmode pulldown selected; 1=Offmode pullup selected
  [12] GPMC_NCS4_OFFMODEPULLUDENABLE rw — OffMode mode pullup/down enable for pad gpmc_ncs4
    values as CONTROL_CORE_PAD0_GPMC_A24_PAD1_GPMC_A25.GPMC_A25_OFFMODEPULLUDENABLE
  [11] GPMC_NCS4_OFFMODEOUTVALUE rw — OffMode mode output value for pad gpmc_ncs4
    0=Set value at 0; 1=Set value at 1
  [10] GPMC_NCS4_OFFMODEOUTENABLE rw — OffMode mode output enable value for pad gpmc_ncs4. This is an active low signal
    0=Output enable; 1=Output disable
  [9] GPMC_NCS4_OFFMODEENABLE rw — OffMode mode override control for pad gpmc_ncs4
    values as CONTROL_CORE_PAD0_GPMC_A24_PAD1_GPMC_A25.GPMC_A25_OFFMODEENABLE
  [8] GPMC_NCS4_INPUTENABLE rw — Input enable value for pad gpmc_ncs4
    values as CONTROL_CORE_PAD0_GPMC_A24_PAD1_GPMC_A25.GPMC_A25_INPUTENABLE
  [4] GPMC_NCS4_PULLTYPESELECT rw — pullup/down selection for pad gpmc_ncs4
    0=pulldown selected; 1=pullup selected
  [3] GPMC_NCS4_PULLUDENABLE rw — pullup/down enable for pad gpmc_cs4
    0=pullup/down disabled; 1=pullup/down enabled
  [2:0] GPMC_NCS4_MUXMODE rw — Functional multiplexing selection for pad gpmc_ncs4
    0=Select gpmc_ncs4; 1=Select dsi1_te0; 2=Select c2c_clkin0; 3=Select gpio_101; 4=Select sys_ndmareq1; 7=Select safe_mode
0x94 CONTROL_CORE_PAD0_GPMC_NCS6_PAD1_GPMC_NCS7 — Register control for Pads gpmc_ncs6 and gpmc_ncs7 Access conditions. Read: unrestricted, Write: unrestricted
  [31] GPMC_NCS7_WAKEUPEVENT ro — Pad_x wake-up event status latched in the IO
    0=GPMC_NCS7_WAKEUPEVENT_0_r (No wake-up event occurred); 1=GPMC_NCS7_WAKEUPEVENT_1_r (A wake-up event occurred)
  [30] GPMC_NCS7_WAKEUPENABLE rw — Input pad wake-up enable (and OFF mode input enable value)
    values as CONTROL_CORE_PAD0_GPMC_A24_PAD1_GPMC_A25.GPMC_A25_WAKEUPENABLE
  [29] GPMC_NCS7_OFFMODEPULLTYPESELECT rw — OffMode mode pullup/down selection for pad gpmc_ncs7
    0=Offmode pulldown selected; 1=Offmode pullup selected
  [28] GPMC_NCS7_OFFMODEPULLUDENABLE rw — OffMode mode pullup/down enable for pad gpmc_ncs7
    values as CONTROL_CORE_PAD0_GPMC_A24_PAD1_GPMC_A25.GPMC_A25_OFFMODEPULLUDENABLE
  [27] GPMC_NCS7_OFFMODEOUTVALUE rw — OffMode mode output value for pad gpmc_ncs7
    0=Set value at 0; 1=Set value at 1
  [26] GPMC_NCS7_OFFMODEOUTENABLE rw — OffMode mode output enable value for pad gpmc_ncs7. This is an active low signal
    0=Output enable; 1=Output disable
  [25] GPMC_NCS7_OFFMODEENABLE rw — OffMode mode override control for pad gpmc_ncs7
    values as CONTROL_CORE_PAD0_GPMC_A24_PAD1_GPMC_A25.GPMC_A25_OFFMODEENABLE
  [24] GPMC_NCS7_INPUTENABLE rw — Input enable value for pad gpmc_ncs7
    values as CONTROL_CORE_PAD0_GPMC_A24_PAD1_GPMC_A25.GPMC_A25_INPUTENABLE
  [20] GPMC_NCS7_PULLTYPESELECT rw — pullup/down selection for pad gpmc_ncs7
    0=pulldown selected; 1=pullup selected
  [19] GPMC_NCS7_PULLUDENABLE rw — pullup/down enable for pad gpmc_ncs7
    0=pullup/down disabled; 1=pullup/down enabled
  [18:16] GPMC_NCS7_MUXMODE rw — Functional multiplexing selection for pad gpmc_ncs7
    0=Select gpmc_ncs7; 1=Select dsi2_te1; 2=Select c2c_dataout1; 3=Select gpio_104; 7=Select safe_mode
  [15] GPMC_NCS6_WAKEUPEVENT ro — Pad_x wake-up event status latched in the IO
    0=GPMC_NCS6_WAKEUPEVENT_0_r (No wake-up event occurred); 1=GPMC_NCS6_WAKEUPEVENT_1_r (A wake-up event occurred)
  [14] GPMC_NCS6_WAKEUPENABLE rw — Input pad wake-up enable (and OFF mode input enable value)
    values as CONTROL_CORE_PAD0_GPMC_A24_PAD1_GPMC_A25.GPMC_A25_WAKEUPENABLE
  [13] GPMC_NCS6_OFFMODEPULLTYPESELECT rw — OffMode mode pullup/down selection for pad gpmc_ncs6
    0=Offmode pulldown selected; 1=Offmode pullup selected
  [12] GPMC_NCS6_OFFMODEPULLUDENABLE rw — OffMode mode pullup/down enable for pad gpmc_ncs6
    values as CONTROL_CORE_PAD0_GPMC_A24_PAD1_GPMC_A25.GPMC_A25_OFFMODEPULLUDENABLE
  [11] GPMC_NCS6_OFFMODEOUTVALUE rw — OffMode mode output value for pad gpmc_ncs6
    0=Set value at 0; 1=Set value at 1
  [10] GPMC_NCS6_OFFMODEOUTENABLE rw — OffMode mode output enable value for pad gpmc_ncs6. This is an active low signal
    0=Output enable; 1=Output disable
  [9] GPMC_NCS6_OFFMODEENABLE rw — OffMode mode override control for pad gpmc_ncs6
    values as CONTROL_CORE_PAD0_GPMC_A24_PAD1_GPMC_A25.GPMC_A25_OFFMODEENABLE
  [8] GPMC_NCS6_INPUTENABLE rw — Input enable value for pad gpmc_ncs6
    values as CONTROL_CORE_PAD0_GPMC_A24_PAD1_GPMC_A25.GPMC_A25_INPUTENABLE
  [4] GPMC_NCS6_PULLTYPESELECT rw — pullup/down selection for pad gpmc_ncs6
    0=pulldown selected; 1=pullup selected
  [3] GPMC_NCS6_PULLUDENABLE rw — pullup/down enable for pad gpmc_ncs6
    0=pullup/down disabled; 1=pullup/down enabled
  [2:0] GPMC_NCS6_MUXMODE rw — Functional multiplexing selection for pad gpmc_ncs6
    0=Select gpmc_ncs6; 1=Select dsi2_te0; 2=Select c2c_dataout0; 3=Select gpio_103; 4=Select sys_ndmareq3; 7=Select safe_mode
0x98 CONTROL_CORE_PAD0_GPIO63_PAD1_GPIO64 reset 0x11F010F — Register control for Pads gpio63 and gpio64 Access conditions. Read: unrestricted, Write: unrestricted
  [31] GPIO64_WAKEUPEVENT ro — Pad_x wake-up event status latched in the IO
    0=GPIO64_WAKEUPEVENT_0_r (No wake-up event occurred); 1=GPIO64_WAKEUPEVENT_1_r (A wake-up event occurred)
  [30] GPIO64_WAKEUPENABLE rw — Input pad wake-up enable (and OFF mode input enable value)
    values as CONTROL_CORE_PAD0_GPMC_A24_PAD1_GPMC_A25.GPMC_A25_WAKEUPENABLE
  [29] GPIO64_OFFMODEPULLTYPESELECT rw — OffMode mode pullup/down selection for pad gpio64
    0=Offmode pulldown selected; 1=Offmode pullup selected
  [28] GPIO64_OFFMODEPULLUDENABLE rw — OffMode mode pullup/down enable for pad gpio64
    values as CONTROL_CORE_PAD0_GPMC_A24_PAD1_GPMC_A25.GPMC_A25_OFFMODEPULLUDENABLE
  [27] GPIO64_OFFMODEOUTVALUE rw — OffMode mode output value for pad gpio64
    0=Set value at 0; 1=Set value at 1
  [26] GPIO64_OFFMODEOUTENABLE rw — OffMode mode output enable value for pad gpio64. This is an active low signal
    0=Output enable; 1=Output disable
  [25] GPIO64_OFFMODEENABLE rw — OffMode mode override control for pad gpio64
    values as CONTROL_CORE_PAD0_GPMC_A24_PAD1_GPMC_A25.GPMC_A25_OFFMODEENABLE
  [24] GPIO64_INPUTENABLE rw — Input enable value for pad gpio64
    values as CONTROL_CORE_PAD0_GPMC_A24_PAD1_GPMC_A25.GPMC_A25_INPUTENABLE
  [20] GPIO64_PULLTYPESELECT rw — pullup/down selection for pad gpio64
    0=pulldown selected; 1=pullup selected
  [19] GPIO64_PULLUDENABLE rw — pullup/down enable for pad gpio64
    0=pullup/down disabled; 1=pullup/down enabled
  [18:16] GPIO64_MUXMODE rw — Functional multiplexing selection for pad gpio64
    3=Select gpio_64; 7=Select safe_mode
  [15] GPIO63_WAKEUPEVENT ro — Pad_x wake-up event status latched in the IO
    0=GPIO63_WAKEUPEVENT_0_r (No wake-up event occurred); 1=GPIO63_WAKEUPEVENT_1_r (A wake-up event occurred)
  [14] GPIO63_WAKEUPENABLE rw — Input pad wake-up enable (and OFF mode input enable value)
    values as CONTROL_CORE_PAD0_GPMC_A24_PAD1_GPMC_A25.GPMC_A25_WAKEUPENABLE
  [13] GPIO63_OFFMODEPULLTYPESELECT rw — OffMode mode pullup/down selection for pad gpio63
    0=Offmode pulldown selected; 1=Offmode pullup selected
  [12] GPIO63_OFFMODEPULLUDENABLE rw — OffMode mode pullup/down enable for pad gpio63
    values as CONTROL_CORE_PAD0_GPMC_A24_PAD1_GPMC_A25.GPMC_A25_OFFMODEPULLUDENABLE
  [11] GPIO63_OFFMODEOUTVALUE rw — OffMode mode output value for pad gpio63
    0=Set value at 0; 1=Set value at 1
  [10] GPIO63_OFFMODEOUTENABLE rw — OffMode mode output enable value for pad gpio63. This is an active low signal
    0=Output enable; 1=Output disable
  [9] GPIO63_OFFMODEENABLE rw — OffMode mode override control for pad gpio63
    values as CONTROL_CORE_PAD0_GPMC_A24_PAD1_GPMC_A25.GPMC_A25_OFFMODEENABLE
  [8] GPIO63_INPUTENABLE rw — Input enable value for pad gpio63
    values as CONTROL_CORE_PAD0_GPMC_A24_PAD1_GPMC_A25.GPMC_A25_INPUTENABLE
  [4] GPIO63_PULLTYPESELECT rw — pullup/down selection for pad gpio63
    0=pulldown selected; 1=pullup selected
  [3] GPIO63_PULLUDENABLE rw — pullup/down enable for pad gpio63
    0=pullup/down disabled; 1=pullup/down enabled
  [2:0] GPIO63_MUXMODE rw — Functional multiplexing selection for pad gpio63
    3=Select gpio_63; 7=Select safe_mode
0x9C CONTROL_CORE_PAD0_GPIO65_PAD1_GPIO66 reset 0x11F011F — Register control for Pads gpio65 and gpio66 Access conditions. Read: unrestricted, Write: unrestricted
  [31] GPIO66_WAKEUPEVENT ro — Pad_x wake-up event status latched in the IO
    0=GPIO66_WAKEUPEVENT_0_r (No wake-up event occurred); 1=GPIO66_WAKEUPEVENT_1_r (A wake-up event occurred)
  [30] GPIO66_WAKEUPENABLE rw — Input pad wake-up enable (and OFF mode input enable value)
    values as CONTROL_CORE_PAD0_GPMC_A24_PAD1_GPMC_A25.GPMC_A25_WAKEUPENABLE
  [29] GPIO66_OFFMODEPULLTYPESELECT rw — OffMode mode pullup/down selection for pad gpio66
    0=Offmode pulldown selected; 1=Offmode pullup selected
  [28] GPIO66_OFFMODEPULLUDENABLE rw — OffMode mode pullup/down enable for pad gpio66
    values as CONTROL_CORE_PAD0_GPMC_A24_PAD1_GPMC_A25.GPMC_A25_OFFMODEPULLUDENABLE
  [27] GPIO66_OFFMODEOUTVALUE rw — OffMode mode output value for pad gpio66
    0=Set value at 0; 1=Set value at 1
  [26] GPIO66_OFFMODEOUTENABLE rw — OffMode mode output enable value for pad gpio66. This is an active low signal
    0=Output enable; 1=Output disable
  [25] GPIO66_OFFMODEENABLE rw — OffMode mode override control for pad gpio66
    values as CONTROL_CORE_PAD0_GPMC_A24_PAD1_GPMC_A25.GPMC_A25_OFFMODEENABLE
  [24] GPIO66_INPUTENABLE rw — Input enable value for pad gpio66
    values as CONTROL_CORE_PAD0_GPMC_A24_PAD1_GPMC_A25.GPMC_A25_INPUTENABLE
  [20] GPIO66_PULLTYPESELECT rw — pullup/down selection for pad gpio66
    0=pulldown selected; 1=pullup selected
  [19] GPIO66_PULLUDENABLE rw — pullup/down enable for pad gpio66
    0=pullup/down disabled; 1=pullup/down enabled
  [18:16] GPIO66_MUXMODE rw — Functional multiplexing selection for pad gpio66
    3=Select gpio_66; 7=Select safe_mode
  [15] GPIO65_WAKEUPEVENT ro — Pad_x wake-up event status latched in the IO
    0=GPIO65_WAKEUPEVENT_0_r (No wake-up event occurred); 1=GPIO65_WAKEUPEVENT_1_r (A wake-up event occurred)
  [14] GPIO65_WAKEUPENABLE rw — Input pad wake-up enable (and OFF mode input enable value)
    values as CONTROL_CORE_PAD0_GPMC_A24_PAD1_GPMC_A25.GPMC_A25_WAKEUPENABLE
  [13] GPIO65_OFFMODEPULLTYPESELECT rw — OffMode mode pullup/down selection for pad gpio65
    0=Offmode pulldown selected; 1=Offmode pullup selected
  [12] GPIO65_OFFMODEPULLUDENABLE rw — OffMode mode pullup/down enable for pad gpio65
    values as CONTROL_CORE_PAD0_GPMC_A24_PAD1_GPMC_A25.GPMC_A25_OFFMODEPULLUDENABLE
  [11] GPIO65_OFFMODEOUTVALUE rw — OffMode mode output value for pad GPIO65
    0=Set value at 0; 1=Set value at 1
  [10] GPIO65_OFFMODEOUTENABLE rw — OffMode mode output enable value for pad gpio65. This is an active low signal
    0=Output enable; 1=Output disable
  [9] GPIO65_OFFMODEENABLE rw — OffMode mode override control for pad gpio65
    values as CONTROL_CORE_PAD0_GPMC_A24_PAD1_GPMC_A25.GPMC_A25_OFFMODEENABLE
  [8] GPIO65_INPUTENABLE rw — Input enable value for pad gpio65
    values as CONTROL_CORE_PAD0_GPMC_A24_PAD1_GPMC_A25.GPMC_A25_INPUTENABLE
  [4] GPIO65_PULLTYPESELECT rw — pullup/down selection for pad gpio65
    0=pulldown selected; 1=pullup selected
  [3] GPIO65_PULLUDENABLE rw — pullup/down enable for pad gpio65
    0=pullup/down disabled; 1=pullup/down enabled
  [2:0] GPIO65_MUXMODE rw — Functional multiplexing selection for pad gpio65
    3=Select gpio_65; 7=Select safe_mode
